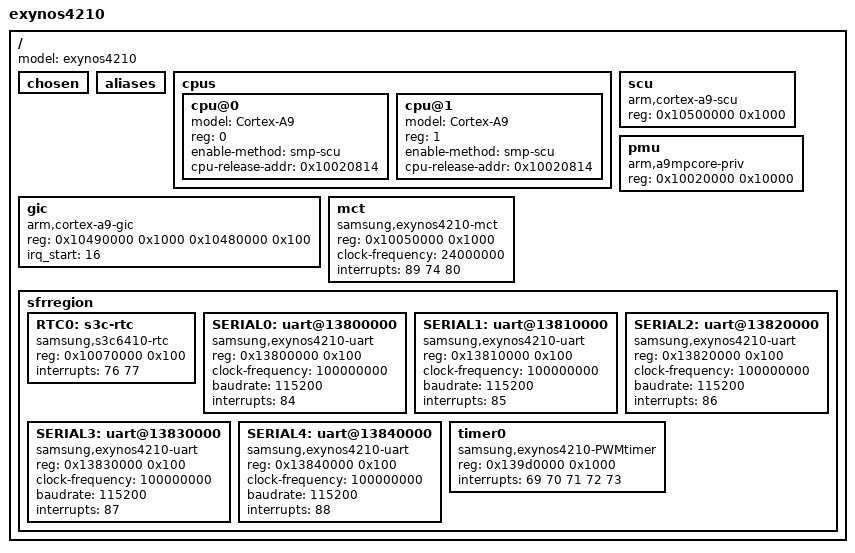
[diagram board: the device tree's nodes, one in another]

/ {
	#address-cells = <1>;
	#size-cells = <1>;
	model = "exynos4210";

	chosen { };
	aliases { };

	cpus {
		#address-cells = <1>;
		#size-cells = <0>;

		cpu@0 {
			device_type = "cpu";
			model = "Cortex-A9";
			reg = <0>;
			enable-method = "smp-scu";
			cpu-release-addr = <0x10020814>;
		};

		cpu@1 {
			device_type = "cpu";
			model = "Cortex-A9";
			reg = <1>;
			enable-method = "smp-scu";
			cpu-release-addr = <0x10020814>;
		};
	};

	scu { /* Snoop Control Unit */
		device_type = "scu";
		compatible = "arm,cortex-a9-scu";
		reg = <0x10500000 0x1000>;
	};

	pmu { /* Performance Monitorig Unit */
		device_type = "pmu";
		compatible = "arm,a9mpcore-priv";
		reg = <0x10020000 0x10000>;
	};

	gic {
		device_type = "pic";
		compatible = "arm,cortex-a9-gic";
		reg = <0x10490000 0x1000 0x10480000 0x100>;
		irq_start = <16>;
	};

	mct {
		device_type = "timer";
		compatible = "samsung,exynos4210-mct";
		reg = <0x10050000 0x1000>;
		clock-frequency = <24000000>;
		interrupts = <89 74 80>;
	};

	sfrregion {
		#address-cells = <1>;
		#size-cells = <1>;

		RTC0: s3c-rtc {
			device_type = "rtc";
			compatible = "samsung,s3c6410-rtc";
			reg = <0x10070000 0x100>;
			interrupts = <76 77>;
		};

		SERIAL0: uart@13800000 {
			device_type = "serial";
			compatible = "samsung,exynos4210-uart";
			reg = <0x13800000 0x100>;
			clock-frequency = <100000000>;
			baudrate = <115200>;
			interrupts = <84>;
		};

		SERIAL1: uart@13810000 {
			device_type = "serial";
			compatible = "samsung,exynos4210-uart";
			reg = <0x13810000 0x100>;
			clock-frequency = <100000000>;
			baudrate = <115200>;
			interrupts = <85>;
		};

		SERIAL2: uart@13820000 {
			device_type = "serial";
			compatible = "samsung,exynos4210-uart";
			reg = <0x13820000 0x100>;
			clock-frequency = <100000000>;
			baudrate = <115200>;
			interrupts = <86>;
		};

		SERIAL3: uart@13830000 {
			device_type = "serial";
			compatible = "samsung,exynos4210-uart";
			reg = <0x13830000 0x100>;
			clock-frequency = <100000000>;
			baudrate = <115200>;
			interrupts = <87>;
		};

		SERIAL4: uart@13840000 {
			device_type = "serial";
			compatible = "samsung,exynos4210-uart";
			reg = <0x13840000 0x100>;
			clock-frequency = <100000000>;
			baudrate = <115200>;
			interrupts = <88>;
		};

		timer0 {
			device_type = "timer";
			compatible = "samsung,exynos4210-PWMtimer";
			reg = <0x139d0000 0x1000>;
			interrupts = <69 70 71 72 73>;
		};
	};
};
